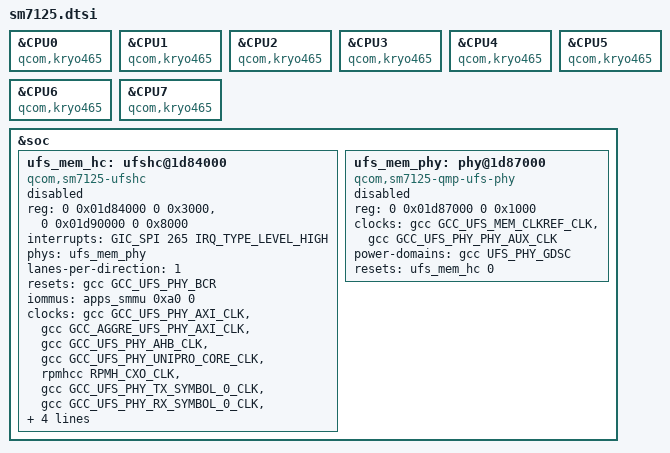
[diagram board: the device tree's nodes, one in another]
// SPDX-License-Identifier: GPL-2.0
/*
 * Copyright (c) 2023, map220v <map220v300@gmail.com>
 */

#include "sc7180.dtsi"

/* SM7125 uses Kryo 465 instead of Kryo 468 */
&CPU0 { compatible = "qcom,kryo465"; };
&CPU1 { compatible = "qcom,kryo465"; };
&CPU2 { compatible = "qcom,kryo465"; };
&CPU3 { compatible = "qcom,kryo465"; };
&CPU4 { compatible = "qcom,kryo465"; };
&CPU5 {	compatible = "qcom,kryo465"; };
&CPU6 { compatible = "qcom,kryo465"; };
&CPU7 { compatible = "qcom,kryo465"; };

&soc {
	ufs_mem_hc: ufshc@1d84000 {
		compatible = "qcom,sm7125-ufshc", "qcom,ufshc",
			     "jedec,ufs-2.0";
		reg = <0 0x01d84000 0 0x3000>,
		      <0 0x01d90000 0 0x8000>;
		reg-names = "std", "ice";
		interrupts = <GIC_SPI 265 IRQ_TYPE_LEVEL_HIGH>;
		phys = <&ufs_mem_phy>;
		phy-names = "ufsphy";
		lanes-per-direction = <1>;
		#reset-cells = <1>;
		resets = <&gcc GCC_UFS_PHY_BCR>;
		reset-names = "rst";

		iommus = <&apps_smmu 0xa0 0>;

		clock-names =
			"core_clk",
			"bus_aggr_clk",
			"iface_clk",
			"core_clk_unipro",
			"ref_clk",
			"tx_lane0_sync_clk",
			"rx_lane0_sync_clk",
			"ice_core_clk";
		clocks =
			<&gcc GCC_UFS_PHY_AXI_CLK>,
			<&gcc GCC_AGGRE_UFS_PHY_AXI_CLK>,
			<&gcc GCC_UFS_PHY_AHB_CLK>,
			<&gcc GCC_UFS_PHY_UNIPRO_CORE_CLK>,
			<&rpmhcc RPMH_CXO_CLK>,
			<&gcc GCC_UFS_PHY_TX_SYMBOL_0_CLK>,
			<&gcc GCC_UFS_PHY_RX_SYMBOL_0_CLK>,
			<&gcc GCC_UFS_PHY_ICE_CORE_CLK>;
		freq-table-hz =
			<50000000 200000000>,
			<0 0>,
			<0 0>,
			<37500000 150000000>,
			<0 0>,
			<0 0>,
			<0 0>,
			<0 300000000>;

		status = "disabled";
	};

	ufs_mem_phy: phy@1d87000 {
		compatible = "qcom,sm7125-qmp-ufs-phy";
		reg = <0 0x01d87000 0 0x1000>;
		#address-cells = <2>;
		#size-cells = <2>;
		ranges;
		clock-names = "ref",
			      "ref_aux";
		clocks = <&gcc GCC_UFS_MEM_CLKREF_CLK>,
		         <&gcc GCC_UFS_PHY_PHY_AUX_CLK>;

		power-domains = <&gcc UFS_PHY_GDSC>;

		resets = <&ufs_mem_hc 0>;
		reset-names = "ufsphy";

		#phy-cells = <0>;

		status = "disabled";
	};
};
